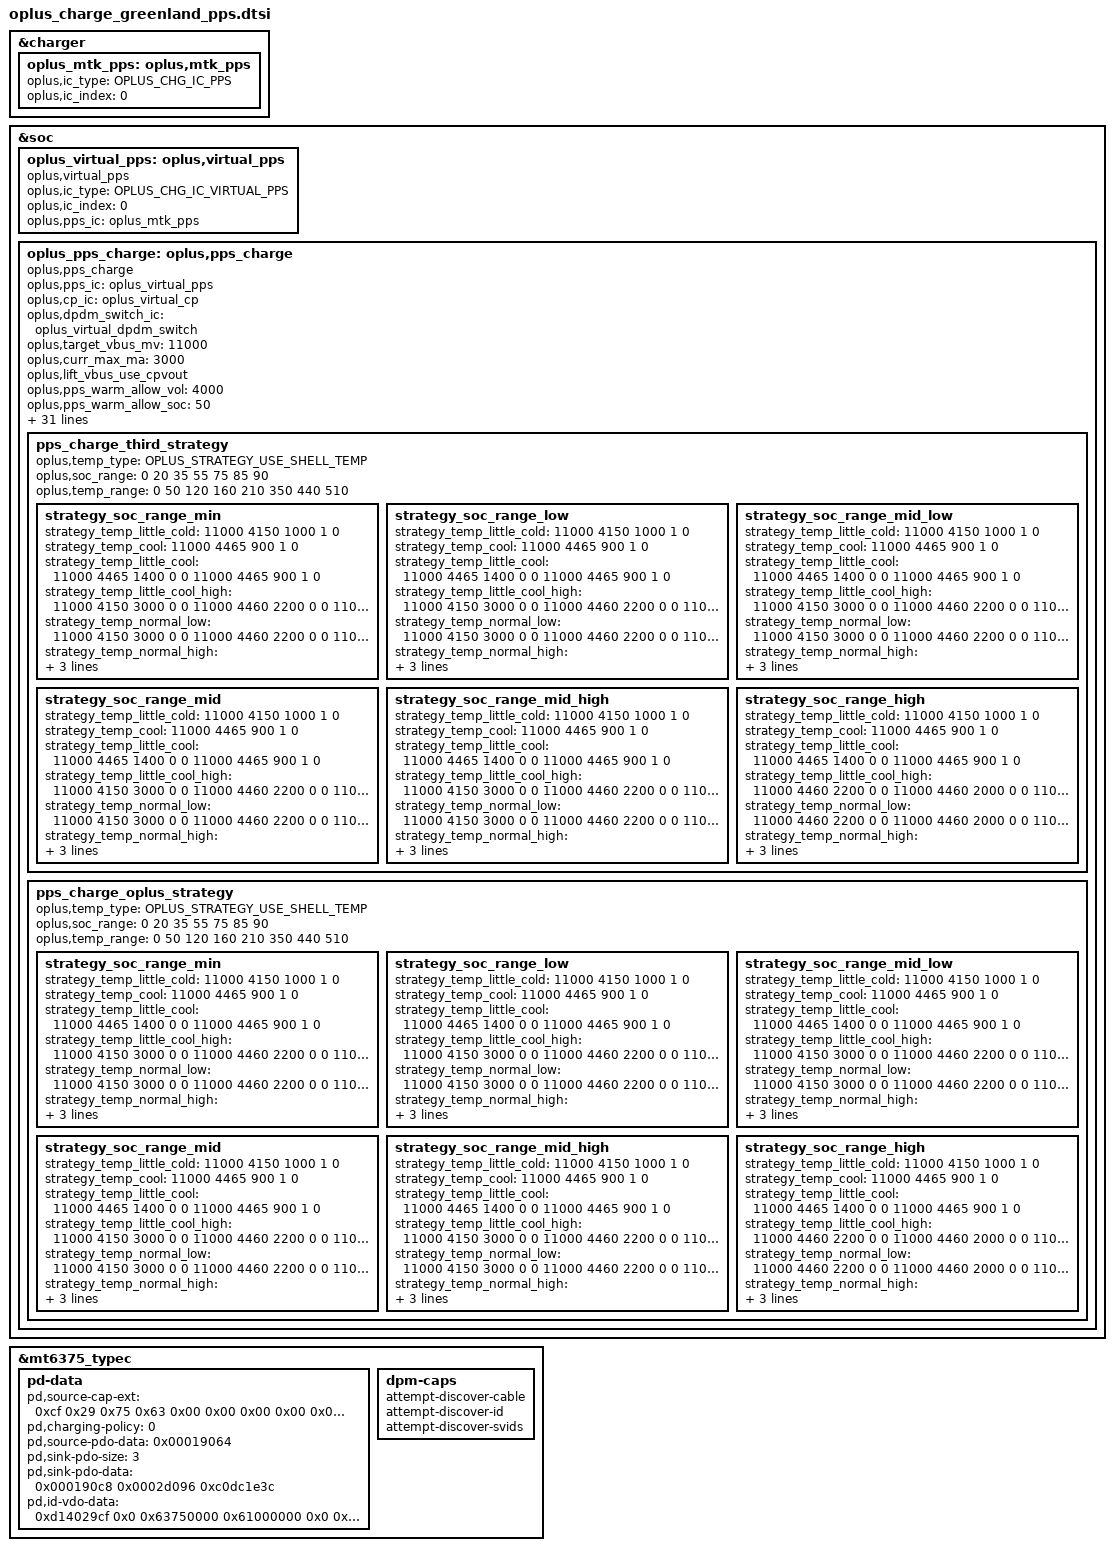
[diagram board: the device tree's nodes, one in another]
&charger {
	oplus_mtk_pps: oplus,mtk_pps {
		oplus,ic_type = <OPLUS_CHG_IC_PPS>;
		oplus,ic_index = <0>;
	};
};
&soc {
	oplus_virtual_pps: oplus,virtual_pps {
		compatible = "oplus,virtual_pps";

		oplus,ic_type = <OPLUS_CHG_IC_VIRTUAL_PPS>;
		oplus,ic_index = <0>;
		oplus,pps_ic = <&oplus_mtk_pps>;
	};
	oplus_pps_charge: oplus,pps_charge {
		compatible = "oplus,pps_charge";
		oplus,pps_ic = <&oplus_virtual_pps>;
		oplus,cp_ic = <&oplus_virtual_cp>;
		oplus,dpdm_switch_ic = <&oplus_virtual_dpdm_switch>;

		oplus,target_vbus_mv = <11000>;
		oplus,curr_max_ma = <3000>;
		oplus,lift_vbus_use_cpvout;

		oplus,pps_warm_allow_vol = <4000>;
		oplus,pps_warm_allow_soc = <50>;
		oplus,pps_strategy_normal_current = <3000>;
		oplus,pps_over_high_or_low_current = <3000>;
		oplus,pps_timeout_third = <25200>;
		oplus,pps_timeout_oplus = <25200>;
		oplus,pps_ibat_over_third = <7400>;
		oplus,pps_ibat_over_oplus = <7400>;
		oplus,pps_full_cool_sw_vbat = <4465>;
		oplus,pps_full_normal_sw_vbat = <4465>;
		oplus,pps_full_normal_hw_vbat = <4475>;
		oplus,pps_full_ffc_vbat = <4465>;
		oplus,pps_full_warm_vbat = <4130>;
		oplus,pps_full_cool_sw_vbat_third = <4465>;
		oplus,pps_full_normal_sw_vbat_third= <4465>;
		oplus,pps_full_normal_hw_vbat_third = <4475>;
		oplus,pps_current_change_timeout = <100>;
		oplus,pps_low_temp = <50>;
		oplus,curve_strategy_name = "pps_ufcs_curve_v2";
		oplus,pps_strategy_batt_high_temp = <410 420 430 400 410 420>;
		oplus,pps_strategy_high_current = <3000 2000 2000 3000 3000 3000>;
		oplus,pps_little_cool_high_temp = <210>;
		oplus,pps_charge_strategy_soc = <0 20 35 55 75 85 90>;
		oplus,pps_charge_strategy_temp = <0 50 120 160 350 440 510>;
		oplus,temperature_strategy_name = "cgcl";
		oplus,temperature_strategy_data = <OPLUS_STRATEGY_USE_SHELL_TEMP
						0   420 3000 1 0
						410 440 2000 1 0>;


		oplus,plc_strategy-data = <&pps_simple_strategy>;
		oplus,plc_strategy-names = "default";

		pps_charge_third_strategy {
			oplus,temp_type = <OPLUS_STRATEGY_USE_SHELL_TEMP>;
			oplus,soc_range = <0 20 35 55 75 85 90>;
			oplus,temp_range = <0 50 120 160 210 350 440 510>;

			strategy_soc_range_min {/* ui_soc: 0%~20% */
				strategy_temp_little_cold = <11000 4150 1000 1 0>;  //0-5
				strategy_temp_cool = <11000 4465 900 1 0>;   //5-12
				strategy_temp_little_cool =	<11000 4465 1400 0 0  //12-16
								11000 4465 900 1 0>;
				strategy_temp_little_cool_high = <11000 4150 3000 0 0  //16-20
								11000 4460 2200 0 0
								11000 4460 2000 0 0
								11000 4460 1500 0 0
								11000 4465 1000 1 0>;
				strategy_temp_normal_low = <11000 4150 3000 0 0 //20-35
								11000 4460 2200 0 0
								11000 4460 2000 0 0
								11000 4460 1500 0 0
								11000 4465 1000 1 0>;
				strategy_temp_normal_high = <11000 4150 3000 0 0  //35-44
								11000 4460 2200 0 0
								11000 4460 2000 0 0
								11000 4460 1500 0 0
								11000 4465 1000 1 0>;
				strategy_temp_warm = <11000 4130 2700 0 0  //44-51
								11000 4130 2200 0 0
								11000 4130 2000 0 0
								11000 4130 1500 0 0
								11000 4130 1000 1 0>;
			};
			strategy_soc_range_low {/* ui_soc: 21%~35% */
				strategy_temp_little_cold = <11000 4150 1000 1 0>;  //0-5
				strategy_temp_cool = <11000 4465 900 1 0>;   //5-12
				strategy_temp_little_cool =	<11000 4465 1400 0 0  //12-16
								11000 4465 900 1 0>;
				strategy_temp_little_cool_high = <11000 4150 3000 0 0  //16-20
								11000 4460 2200 0 0
								11000 4460 2000 0 0
								11000 4460 1500 0 0
								11000 4465 1000 1 0>;
				strategy_temp_normal_low = <11000 4150 3000 0 0 //20-35
								11000 4460 2200 0 0
								11000 4460 2000 0 0
								11000 4460 1500 0 0
								11000 4465 1000 1 0>;
				strategy_temp_normal_high = <11000 4150 3000 0 0  //35-44
								11000 4460 2200 0 0
								11000 4460 2000 0 0
								11000 4460 1500 0 0
								11000 4465 1000 1 0>;
				strategy_temp_warm = <11000 4130 2700 0 0  //44-51
								11000 4130 2200 0 0
								11000 4130 2000 0 0
								11000 4130 1500 0 0
								11000 4130 1000 1 0>;
			};
			strategy_soc_range_mid_low {/* ui_soc: 36%~50% */
				strategy_temp_little_cold = <11000 4150 1000 1 0>;  //0-5
				strategy_temp_cool = <11000 4465 900 1 0>;   //5-12
				strategy_temp_little_cool =	<11000 4465 1400 0 0  //12-16
								11000 4465 900 1 0>;
				strategy_temp_little_cool_high = <11000 4150 3000 0 0  //16-20
								11000 4460 2200 0 0
								11000 4460 2000 0 0
								11000 4460 1500 0 0
								11000 4465 1000 1 0>;
				strategy_temp_normal_low = <11000 4150 3000 0 0 //20-35
								11000 4460 2200 0 0
								11000 4460 2000 0 0
								11000 4460 1500 0 0
								11000 4465 1000 1 0>;
				strategy_temp_normal_high = <11000 4150 3000 0 0  //35-44
								11000 4460 2200 0 0
								11000 4460 2000 0 0
								11000 4460 1500 0 0
								11000 4465 1000 1 0>;
				strategy_temp_warm = <11000 4130 2700 0 0  //44-51
								11000 4130 2200 0 0
								11000 4130 2000 0 0
								11000 4130 1500 0 0
								11000 4130 1000 1 0>;
			};
			strategy_soc_range_mid { /* ui_soc: 51%~75% */
				strategy_temp_little_cold = <11000 4150 1000 1 0>;  //0-5
				strategy_temp_cool = <11000 4465 900 1 0>;   //5-12
				strategy_temp_little_cool =	<11000 4465 1400 0 0  //12-16
								11000 4465 900 1 0>;
				strategy_temp_little_cool_high = <11000 4150 3000 0 0  //16-20
								11000 4460 2200 0 0
								11000 4460 2000 0 0
								11000 4460 1500 0 0
								11000 4465 1000 1 0>;
				strategy_temp_normal_low = <11000 4150 3000 0 0 //20-35
								11000 4460 2200 0 0
								11000 4460 2000 0 0
								11000 4460 1500 0 0
								11000 4465 1000 1 0>;
				strategy_temp_normal_high = <11000 4150 3000 0 0  //35-44
								11000 4460 2200 0 0
								11000 4460 2000 0 0
								11000 4460 1500 0 0
								11000 4465 1000 1 0>;
				strategy_temp_warm = <11000 4130 2700 0 0  //44-51
								11000 4130 2200 0 0
								11000 4130 2000 0 0
								11000 4130 1500 0 0
								11000 4130 1000 1 0>;
			};
			strategy_soc_range_mid_high {/* ui_soc: 76%~85% */
				strategy_temp_little_cold = <11000 4150 1000 1 0>;  //0-5
				strategy_temp_cool = <11000 4465 900 1 0>;   //5-12
				strategy_temp_little_cool =	<11000 4465 1400 0 0  //12-16
								11000 4465 900 1 0>;
				strategy_temp_little_cool_high = <11000 4150 3000 0 0  //16-20
								11000 4460 2200 0 0
								11000 4460 2000 0 0
								11000 4460 1500 0 0
								11000 4465 1000 1 0>;
				strategy_temp_normal_low = <11000 4150 3000 0 0 //20-35
								11000 4460 2200 0 0
								11000 4460 2000 0 0
								11000 4460 1500 0 0
								11000 4465 1000 1 0>;
				strategy_temp_normal_high = <11000 4150 3000 0 0  //35-44
								11000 4460 2200 0 0
								11000 4460 2000 0 0
								11000 4460 1500 0 0
								11000 4465 1000 1 0>;
				strategy_temp_warm = <11000 4130 2700 0 0  //44-51
								11000 4130 2200 0 0
								11000 4130 2000 0 0
								11000 4130 1500 0 0
								11000 4130 1000 1 0>;
			};
			strategy_soc_range_high {/* ui_soc: 86%~95% */
				strategy_temp_little_cold = <11000 4150 1000 1 0>;  //0-5
				strategy_temp_cool = <11000 4465 900 1 0>;   //5-12
				strategy_temp_little_cool =	<11000 4465 1400 0 0  //12-16
								11000 4465 900 1 0>;
				strategy_temp_little_cool_high = <11000 4460 2200 0 0  //16-20
								11000 4460 2000 0 0
								11000 4460 1500 0 0
								11000 4465 1000 1 0>;
				strategy_temp_normal_low = <11000 4460 2200 0 0 //20-35
								11000 4460 2000 0 0
								11000 4460 1500 0 0
								11000 4465 1000 1 0>;
				strategy_temp_normal_high = <11000 4460 2200 0 0  //35-44
								11000 4460 2000 0 0
								11000 4460 1500 0 0
								11000 4465 1000 1 0>;
				strategy_temp_warm = <11000 4130 2200 0 0  //44-51
								11000 4130 2000 0 0
								11000 4130 1500 0 0
								11000 4130 1000 1 0>;
			};
		};

		pps_charge_oplus_strategy {
			oplus,temp_type = <OPLUS_STRATEGY_USE_SHELL_TEMP>;
			oplus,soc_range = <0 20 35 55 75 85 90>;
			oplus,temp_range = <0 50 120 160 210 350 440 510>;

			strategy_soc_range_min {
				strategy_temp_little_cold = <11000 4150 1000 1 0>;  //0-5
				strategy_temp_cool = <11000 4465 900 1 0>;   //5-12
				strategy_temp_little_cool =	<11000 4465 1400 0 0  //12-16
								11000 4465 900 1 0>;
				strategy_temp_little_cool_high = <11000 4150 3000 0 0  //16-20
								11000 4460 2200 0 0
								11000 4460 2000 0 0
								11000 4460 1500 0 0
								11000 4465 1000 1 0>;
				strategy_temp_normal_low = <11000 4150 3000 0 0 //20-35
								11000 4460 2200 0 0
								11000 4460 2000 0 0
								11000 4460 1500 0 0
								11000 4465 1000 1 0>;
				strategy_temp_normal_high = <11000 4150 3000 0 0  //35-44
								11000 4460 2200 0 0
								11000 4460 2000 0 0
								11000 4460 1500 0 0
								11000 4465 1000 1 0>;
				strategy_temp_warm = <11000 4130 2700 0 0  //44-51
								11000 4130 2200 0 0
								11000 4130 2000 0 0
								11000 4130 1500 0 0
								11000 4130 1000 1 0>;
			};
			strategy_soc_range_low {
				strategy_temp_little_cold = <11000 4150 1000 1 0>;  //0-5
				strategy_temp_cool = <11000 4465 900 1 0>;   //5-12
				strategy_temp_little_cool =	<11000 4465 1400 0 0  //12-16
								11000 4465 900 1 0>;
				strategy_temp_little_cool_high = <11000 4150 3000 0 0  //16-20
								11000 4460 2200 0 0
								11000 4460 2000 0 0
								11000 4460 1500 0 0
								11000 4465 1000 1 0>;
				strategy_temp_normal_low = <11000 4150 3000 0 0 //20-35
								11000 4460 2200 0 0
								11000 4460 2000 0 0
								11000 4460 1500 0 0
								11000 4465 1000 1 0>;
				strategy_temp_normal_high = <11000 4150 3000 0 0  //35-44
								11000 4460 2200 0 0
								11000 4460 2000 0 0
								11000 4460 1500 0 0
								11000 4465 1000 1 0>;
				strategy_temp_warm = <11000 4130 2700 0 0  //44-51
								11000 4130 2200 0 0
								11000 4130 2000 0 0
								11000 4130 1500 0 0
								11000 4130 1000 1 0>;

			};
			strategy_soc_range_mid_low {
				strategy_temp_little_cold = <11000 4150 1000 1 0>;  //0-5
				strategy_temp_cool = <11000 4465 900 1 0>;   //5-12
				strategy_temp_little_cool =	<11000 4465 1400 0 0  //12-16
								11000 4465 900 1 0>;
				strategy_temp_little_cool_high = <11000 4150 3000 0 0  //16-20
								11000 4460 2200 0 0
								11000 4460 2000 0 0
								11000 4460 1500 0 0
								11000 4465 1000 1 0>;
				strategy_temp_normal_low = <11000 4150 3000 0 0 //20-35
								11000 4460 2200 0 0
								11000 4460 2000 0 0
								11000 4460 1500 0 0
								11000 4465 1000 1 0>;
				strategy_temp_normal_high = <11000 4150 3000 0 0  //35-44
								11000 4460 2200 0 0
								11000 4460 2000 0 0
								11000 4460 1500 0 0
								11000 4465 1000 1 0>;
				strategy_temp_warm = <11000 4130 2700 0 0  //44-51
								11000 4130 2200 0 0
								11000 4130 2000 0 0
								11000 4130 1500 0 0
								11000 4130 1000 1 0>;
			};
			strategy_soc_range_mid {
				strategy_temp_little_cold = <11000 4150 1000 1 0>;  //0-5
				strategy_temp_cool = <11000 4465 900 1 0>;   //5-12
				strategy_temp_little_cool =	<11000 4465 1400 0 0  //12-16
								11000 4465 900 1 0>;
				strategy_temp_little_cool_high = <11000 4150 3000 0 0  //16-20
								11000 4460 2200 0 0
								11000 4460 2000 0 0
								11000 4460 1500 0 0
								11000 4465 1000 1 0>;
				strategy_temp_normal_low = <11000 4150 3000 0 0 //20-35
								11000 4460 2200 0 0
								11000 4460 2000 0 0
								11000 4460 1500 0 0
								11000 4465 1000 1 0>;
				strategy_temp_normal_high = <11000 4150 3000 0 0  //35-44
								11000 4460 2200 0 0
								11000 4460 2000 0 0
								11000 4460 1500 0 0
								11000 4465 1000 1 0>;
				strategy_temp_warm = <11000 4130 2700 0 0  //44-51
								11000 4130 2200 0 0
								11000 4130 2000 0 0
								11000 4130 1500 0 0
								11000 4130 1000 1 0>;
			};
			strategy_soc_range_mid_high {
				strategy_temp_little_cold = <11000 4150 1000 1 0>;  //0-5
				strategy_temp_cool = <11000 4465 900 1 0>;   //5-12
				strategy_temp_little_cool =	<11000 4465 1400 0 0  //12-16
								11000 4465 900 1 0>;
				strategy_temp_little_cool_high = <11000 4150 3000 0 0  //16-20
								11000 4460 2200 0 0
								11000 4460 2000 0 0
								11000 4460 1500 0 0
								11000 4465 1000 1 0>;
				strategy_temp_normal_low = <11000 4150 3000 0 0 //20-35
								11000 4460 2200 0 0
								11000 4460 2000 0 0
								11000 4460 1500 0 0
								11000 4465 1000 1 0>;
				strategy_temp_normal_high = <11000 4150 3000 0 0  //35-44
								11000 4460 2200 0 0
								11000 4460 2000 0 0
								11000 4460 1500 0 0
								11000 4465 1000 1 0>;
				strategy_temp_warm = <11000 4130 2700 0 0  //44-51
								11000 4130 2200 0 0
								11000 4130 2000 0 0
								11000 4130 1500 0 0
								11000 4130 1000 1 0>;
			};
			strategy_soc_range_high {
				strategy_temp_little_cold = <11000 4150 1000 1 0>;  //0-5
				strategy_temp_cool = <11000 4465 900 1 0>;   //5-12
				strategy_temp_little_cool =	<11000 4465 1400 0 0  //12-16
								11000 4465 900 1 0>;
				strategy_temp_little_cool_high = <11000 4460 2200 0 0  //16-20
								11000 4460 2000 0 0
								11000 4460 1500 0 0
								11000 4465 1000 1 0>;
				strategy_temp_normal_low = <11000 4460 2200 0 0 //20-35
								11000 4460 2000 0 0
								11000 4460 1500 0 0
								11000 4465 1000 1 0>;
				strategy_temp_normal_high = <11000 4460 2200 0 0  //35-44
								11000 4460 2000 0 0
								11000 4460 1500 0 0
								11000 4465 1000 1 0>;
				strategy_temp_warm = <11000 4130 2200 0 0  //44-51
								11000 4130 2000 0 0
								11000 4130 1500 0 0
								11000 4130 1000 1 0>;
			};
		};
	};
};

/* for pd common charger */
&mt6375_typec {
	pd-data {
			pd,source-cap-ext = /bits/ 8 <0xcf 0x29 0x75 0x63
							      0x00 0x00 0x00 0x00
							      0x00 0x00 0x00 0x00
							      0x00 0x00 0x00 0x00
							      0x00 0x00 0x00 0x00
							      0x00 0x00 0x01 0x05
							      0x00>;

			pd,charging-policy = <0>;

			pd,source-pdo-data = <0x00019064>;/* Fixed, 5000mV, 1000mA*/

			/*0x000190c8: Fixed, 5000mV, 2000mA*/
			/*0x0002d096: Fixed, 9000mV, 1500mA*/
			/*0xc0dc1e64: apdo, min 3000mV, max 11000mV, 5000mA*/
			/*0xc0dc1e3c: apdo, min 3000mV, max 11000mV, 3000mA*/
			pd,sink-pdo-size = <3>;
			pd,sink-pdo-data = <0x000190c8 0x0002d096 0xc0dc1e3c>;

			/* No DP, host + device */
			pd,id-vdo-data = <0xd14029cf 0x0 0x63750000
						  0x61000000 0x0 0x41000000>;
	};

	dpm-caps {
			// attempt-enter-dp-mode;
			attempt-discover-cable;
			attempt-discover-id;
			attempt-discover-svids;
	};
};

//#endif OPLUS_FEATURE_CHG_BASIC

